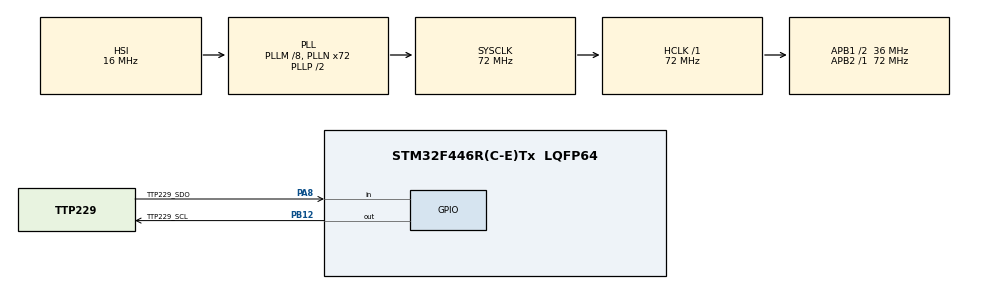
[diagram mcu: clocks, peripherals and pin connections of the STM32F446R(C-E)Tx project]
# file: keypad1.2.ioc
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Mcu.Family=STM32F4
Mcu.Name=STM32F446R(C-E)Tx
Mcu.Package=LQFP64
NVIC.PriorityGroup=NVIC_PRIORITYGROUP_0
PA8.GPIO_Label=TTP229_SDO
PA8.Signal=GPIO_Input
PB12.GPIO_Label=TTP229_SCL
PB12.Signal=GPIO_Output
PH0-OSC_IN.Mode=HSE-External-Oscillator
PH0-OSC_IN.Signal=RCC_OSC_IN
PH1-OSC_OUT.Mode=HSE-External-Oscillator
PH1-OSC_OUT.Signal=RCC_OSC_OUT
ProjectManager.HeapSize=0x200
ProjectManager.StackSize=0x400
ProjectManager.TargetToolchain=STM32CubeIDE
RCC.48MHZClocksFreq_Value=84000000
RCC.AHBFreq_Value=72000000
RCC.APB1CLKDivider=RCC_HCLK_DIV2
RCC.APB1Freq_Value=36000000
RCC.APB1TimFreq_Value=72000000
RCC.APB2Freq_Value=72000000
RCC.APB2TimFreq_Value=72000000
RCC.CortexFreq_Value=72000000
RCC.FLatency-AdvancedSettings=FLASH_LATENCY_2
RCC.HCLKFreq_Value=72000000
RCC.HSE_VALUE=8000000
RCC.HSI_VALUE=16000000
RCC.PLLM=8
RCC.PLLN=72
RCC.SYSCLKFreq_VALUE=72000000
RCC.SYSCLKSource=RCC_SYSCLKSOURCE_PLLCLK
RCC.USBFreq_Value=72000000
RCC.VCOOutputFreq_Value=144000000
board=NUCLEO-F446RE

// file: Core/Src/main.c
/* USER CODE BEGIN Header */
/**
  ******************************************************************************
  * @file           : main.c
  * @brief          : Main program body
  ******************************************************************************
  * @attention
  *
  * Copyright (c) 2025 STMicroelectronics.
  * All rights reserved.
  *
  * This software is licensed under terms that can be found in the LICENSE file
  * in the root directory of this software component.
  * If no LICENSE file comes with this software, it is provided AS-IS.
  *
  ******************************************************************************
  */
/* USER CODE END Header */
#include "main.h"

/* USER CODE BEGIN Includes */
#include "stdio.h"
#include "ttp229.h"
/* USER CODE END Includes */

void SystemClock_Config(void);
static void MX_GPIO_Init(void);

/* USER CODE BEGIN 0 */
uint8_t key;
/* USER CODE END 0 */

int main(void)
{

  /* MCU Configuration--------------------------------------------------------*/

  /* Reset of all peripherals, Initializes the Flash interface and the Systick. */
  HAL_Init();

  /* Configure the system clock */
  SystemClock_Config();

  /* Initialize all configured peripherals */
  MX_GPIO_Init();
  /* USER CODE BEGIN 2 */
  SetSCL(GPIO_PIN_SET);
  /* USER CODE END 2 */

  /* Infinite loop */
  while (1)
  {

    /* USER CODE BEGIN 3 */
	 key = ReadKey16(); // Blocking
  }
  /* USER CODE END 3 */
}

void SystemClock_Config(void)
{
  RCC_OscInitTypeDef RCC_OscInitStruct = {0};
  RCC_ClkInitTypeDef RCC_ClkInitStruct = {0};

  /** Configure the main internal regulator output voltage
  */
  __HAL_RCC_PWR_CLK_ENABLE();
  __HAL_PWR_VOLTAGESCALING_CONFIG(PWR_REGULATOR_VOLTAGE_SCALE3);

  /** Initializes the RCC Oscillators according to the specified parameters
  * in the RCC_OscInitTypeDef structure.
  */
  RCC_OscInitStruct.OscillatorType = RCC_OSCILLATORTYPE_HSI;
  RCC_OscInitStruct.HSIState = RCC_HSI_ON;
  RCC_OscInitStruct.HSICalibrationValue = RCC_HSICALIBRATION_DEFAULT;
  RCC_OscInitStruct.PLL.PLLState = RCC_PLL_ON;
  RCC_OscInitStruct.PLL.PLLSource = RCC_PLLSOURCE_HSI;
  RCC_OscInitStruct.PLL.PLLM = 8;
  RCC_OscInitStruct.PLL.PLLN = 72;
  RCC_OscInitStruct.PLL.PLLP = RCC_PLLP_DIV2;
  RCC_OscInitStruct.PLL.PLLQ = 2;
  RCC_OscInitStruct.PLL.PLLR = 2;
  if (HAL_RCC_OscConfig(&RCC_OscInitStruct) != HAL_OK)
  {
    Error_Handler();
  }

  /** Initializes the CPU, AHB and APB buses clocks
  */
  RCC_ClkInitStruct.ClockType = RCC_CLOCKTYPE_HCLK|RCC_CLOCKTYPE_SYSCLK
                              |RCC_CLOCKTYPE_PCLK1|RCC_CLOCKTYPE_PCLK2;
  RCC_ClkInitStruct.SYSCLKSource = RCC_SYSCLKSOURCE_PLLCLK;
  RCC_ClkInitStruct.AHBCLKDivider = RCC_SYSCLK_DIV1;
  RCC_ClkInitStruct.APB1CLKDivider = RCC_HCLK_DIV2;
  RCC_ClkInitStruct.APB2CLKDivider = RCC_HCLK_DIV1;

  if (HAL_RCC_ClockConfig(&RCC_ClkInitStruct, FLASH_LATENCY_2) != HAL_OK)
  {
    Error_Handler();
  }
}

static void MX_GPIO_Init(void)
{
  GPIO_InitTypeDef GPIO_InitStruct = {0};

  /* GPIO Ports Clock Enable */
  __HAL_RCC_GPIOH_CLK_ENABLE();
  __HAL_RCC_GPIOB_CLK_ENABLE();
  __HAL_RCC_GPIOA_CLK_ENABLE();

  /*Configure GPIO pin Output Level */
  HAL_GPIO_WritePin(TTP229_SCL_GPIO_Port, TTP229_SCL_Pin, GPIO_PIN_RESET);

  /*Configure GPIO pin : TTP229_SCL_Pin */
  GPIO_InitStruct.Pin = TTP229_SCL_Pin;
  GPIO_InitStruct.Mode = GPIO_MODE_OUTPUT_PP;
  GPIO_InitStruct.Pull = GPIO_NOPULL;
  GPIO_InitStruct.Speed = GPIO_SPEED_FREQ_LOW;
  HAL_GPIO_Init(TTP229_SCL_GPIO_Port, &GPIO_InitStruct);

  /*Configure GPIO pin : TTP229_SDO_Pin */
  GPIO_InitStruct.Pin = TTP229_SDO_Pin;
  GPIO_InitStruct.Mode = GPIO_MODE_INPUT;
  GPIO_InitStruct.Pull = GPIO_NOPULL;
  HAL_GPIO_Init(TTP229_SDO_GPIO_Port, &GPIO_InitStruct);

}

void Error_Handler(void)
{
  __disable_irq();
  while (1)
  {
  }
}
